VERSION ""

NS_ :

BS_:

BU_: XXX

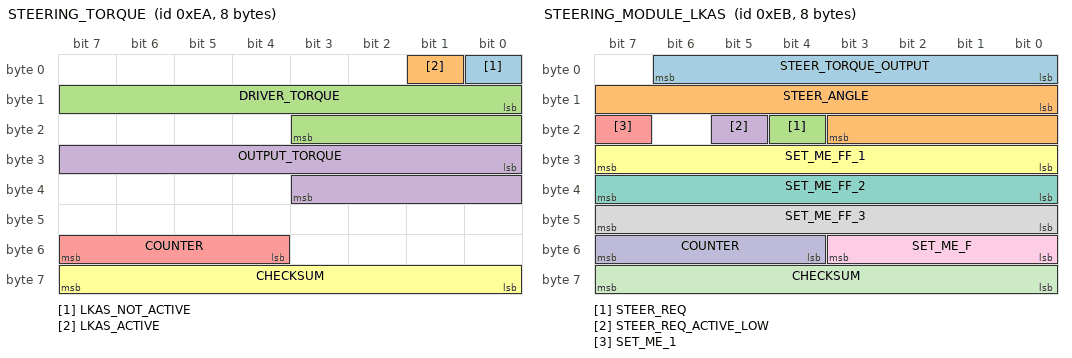
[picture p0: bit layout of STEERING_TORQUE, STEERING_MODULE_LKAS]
BO_ 234 STEERING_TORQUE: 8 XXX
 SG_ LKAS_NOT_ACTIVE : 0|1@0+ (1,0) [0|1] "" XXX
 SG_ LKAS_ACTIVE : 1|1@0+ (1,0) [0|1] "" XXX
 SG_ DRIVER_TORQUE : 8|12@1- (1,0) [0|4095] "" XXX
 SG_ OUTPUT_TORQUE : 24|12@1+ (1,-2000) [0|4095] "" XXX
 SG_ COUNTER : 55|4@0+ (1,0) [0|15] "" XXX
 SG_ CHECKSUM : 63|8@0+ (1,0) [0|255] "" XXX

BO_ 235 STEERING_MODULE_LKAS: 8 XXX
 SG_ STEER_TORQUE_OUTPUT : 0|7@1+ (1,0) [0|255] "" XXX
 SG_ STEER_ANGLE : 8|12@1- (1,0) [0|4095] "" XXX
 SG_ STEER_REQ : 20|1@0+ (1,0) [0|1] "" XXX
 SG_ STEER_REQ_ACTIVE_LOW : 21|1@0+ (1,0) [0|1] "" XXX
 SG_ SET_ME_1 : 23|1@0+ (1,0) [0|1] "" XXX
 SG_ SET_ME_FF_1 : 31|8@0+ (1,0) [0|255] "" XXX
 SG_ SET_ME_FF_2 : 39|8@0+ (1,0) [0|255] "" XXX
 SG_ SET_ME_FF_3 : 47|8@0+ (1,0) [0|255] "" XXX
 SG_ SET_ME_F : 51|4@0+ (1,0) [0|15] "" XXX
 SG_ COUNTER : 55|4@0+ (1,0) [0|15] "" XXX
 SG_ CHECKSUM : 63|8@0+ (1,0) [0|255] "" XXX

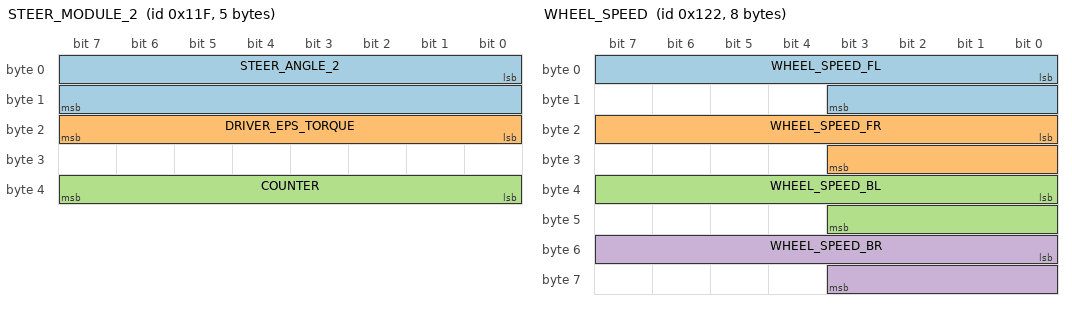
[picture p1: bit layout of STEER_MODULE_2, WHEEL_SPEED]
BO_ 287 STEER_MODULE_2: 5 XXX
 SG_ STEER_ANGLE_2 : 0|16@1- (0.1,0) [0|65535] "deg" XXX
 SG_ DRIVER_EPS_TORQUE : 16|8@1+ (1,0) [0|255] "" XXX
 SG_ COUNTER : 39|8@0+ (1,0) [0|255] "" XXX

BO_ 289 WHEEL_SPEED_1: 8 XXX
 SG_ AVERAGE_WHEEL_SPEED : 0|11@1+ (0.0718,0) [0|2047] "km/h" XXX

BO_ 290 WHEEL_SPEED: 8 XXX
 SG_ WHEEL_SPEED_FL : 0|12@1+ (0.0718,0) [0|65535] "km/h" XXX
 SG_ WHEEL_SPEED_FR : 16|12@1+ (0.0718,0) [0|65535] "km/h" XXX
 SG_ WHEEL_SPEED_BL : 32|12@1+ (0.0718,0) [0|4095] "km/h" XXX
 SG_ WHEEL_SPEED_BR : 48|12@1+ (0.0718,0) [0|65535] "km/h" XXX

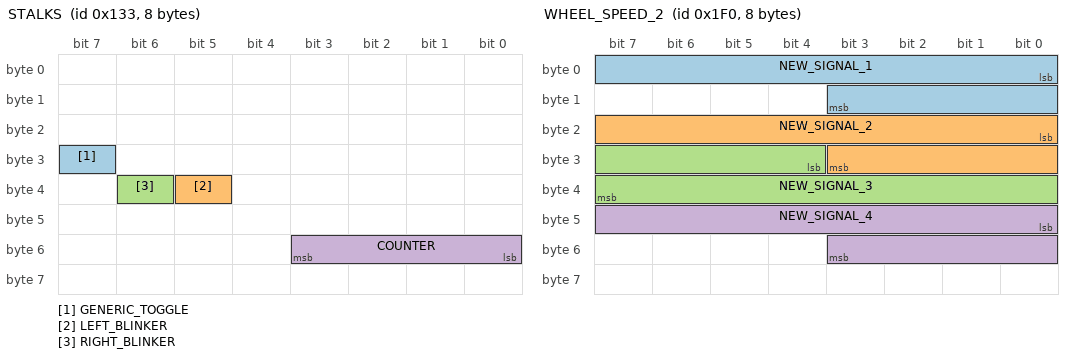
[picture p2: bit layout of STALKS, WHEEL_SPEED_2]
BO_ 307 STALKS: 8 XXX
 SG_ GENERIC_TOGGLE : 31|1@0+ (1,0) [0|1] "" XXX
 SG_ LEFT_BLINKER : 37|1@0+ (1,0) [0|1] "" XXX
 SG_ RIGHT_BLINKER : 38|1@0+ (1,0) [0|1] "" XXX
 SG_ COUNTER : 51|4@0+ (1,0) [0|15] "" XXX

BO_ 496 WHEEL_SPEED_2: 8 XXX
 SG_ NEW_SIGNAL_1 : 0|12@1+ (0.0716,0) [0|4095] "" XXX
 SG_ NEW_SIGNAL_2 : 16|12@1+ (0.0716,0) [0|4095] "" XXX
 SG_ NEW_SIGNAL_3 : 28|12@1+ (0.0716,0) [0|4095] "" XXX
 SG_ NEW_SIGNAL_4 : 40|12@1+ (0.0716,0) [0|4095] "" XXX

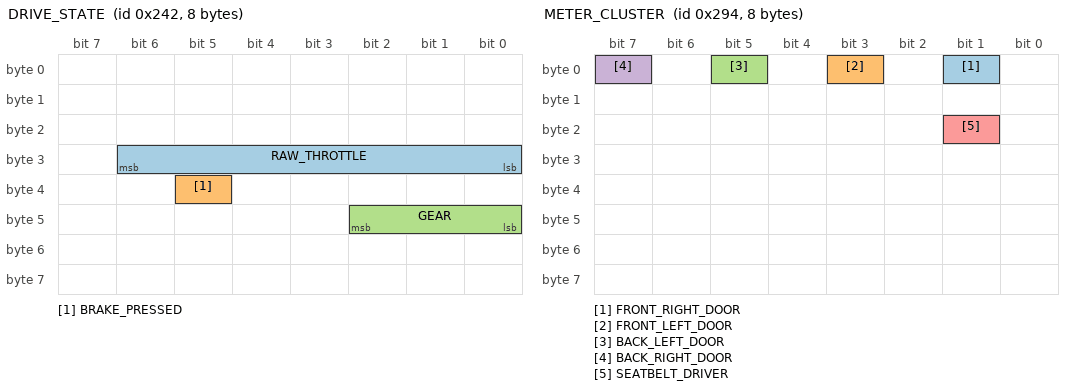
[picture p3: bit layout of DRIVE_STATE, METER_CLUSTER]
BO_ 578 DRIVE_STATE: 8 XXX
 SG_ RAW_THROTTLE : 24|7@1+ (1,0) [0|127] "" XXX
 SG_ BRAKE_PRESSED : 37|1@0+ (1,0) [0|1] "" XXX
 SG_ GEAR : 40|3@1+ (1,0) [0|7] "" XXX

BO_ 660 METER_CLUSTER: 8 XXX
 SG_ FRONT_RIGHT_DOOR : 1|1@0+ (1,0) [0|1] "" XXX
 SG_ FRONT_LEFT_DOOR : 3|1@0+ (1,0) [0|1] "" XXX
 SG_ BACK_LEFT_DOOR : 5|1@0+ (1,0) [0|1] "" XXX
 SG_ BACK_RIGHT_DOOR : 7|1@0+ (1,0) [0|1] "" XXX
 SG_ SEATBELT_DRIVER : 17|1@0+ (1,0) [0|1] "" XXX

BO_ 790 LKAS_HUD_ADAS: 8 XXX
 SG_ HMA : 4|5@0+ (1,0) [0|31] "" XXX
 SG_ STEER_ACTIVE_1_1 : 5|1@0+ (1,0) [0|1] "" XXX
 SG_ LSS_STATE : 7|2@0+ (1,0) [0|3] "" XXX
 SG_ LKAS_X02_1 : 8|2@1+ (1,0) [0|3] "" XXX
 SG_ HAND_WARNING : 10|1@0+ (1,0) [0|1] "" XXX
 SG_ LKAS_X05_1 : 11|5@1+ (1,0) [0|31] "" XXX
 SG_ LKAS_X08_1 : 23|8@0+ (1,0) [0|255] "" XXX
 SG_ LKAS_X08_2 : 31|8@0+ (1,0) [0|255] "" XXX
 SG_ LKAS_X02_2 : 32|2@1+ (1,0) [0|3] "" XXX
 SG_ STEER_ACTIVE_1_3 : 35|1@0+ (1,0) [0|1] "" XXX
 SG_ STEER_ACTIVE_ACTIVE_LOW : 36|1@0+ (1,0) [0|1] "" XXX
 SG_ STEER_ACTIVE_1_2 : 37|1@0+ (1,0) [0|1] "" XXX
 SG_ LKAS_X02_3 : 39|2@0+ (1,0) [0|1] "" XXX
 SG_ LKAS_X08_3 : 47|8@0+ (1,0) [0|255] "" XXX
 SG_ LKAS_X04_1 : 48|4@1+ (1,0) [0|15] "" XXX
 SG_ COUNTER : 55|4@0+ (1,0) [0|15] "" XXX
 SG_ CHECKSUM : 63|8@0+ (1,0) [0|255] "" XXX

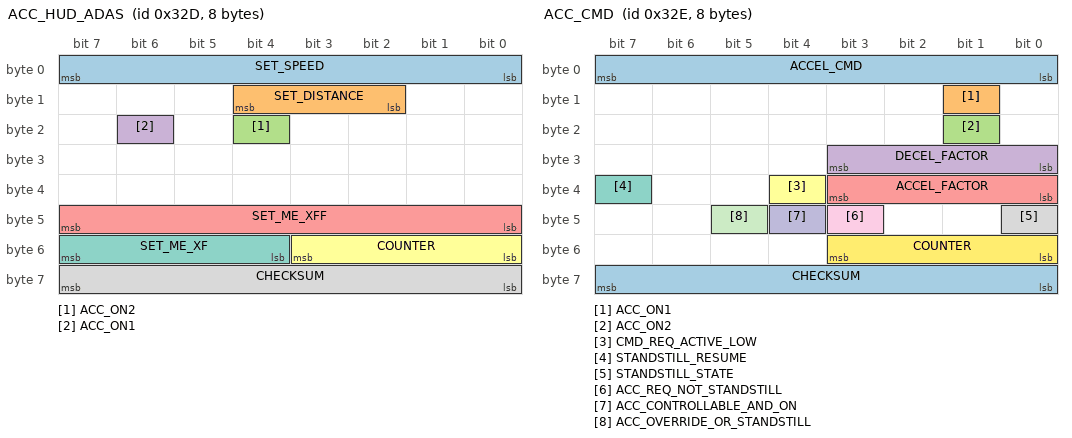
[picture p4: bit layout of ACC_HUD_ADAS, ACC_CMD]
BO_ 813 ACC_HUD_ADAS: 8 XXX
 SG_ SET_SPEED : 0|8@1+ (0.5,0) [0|255] "" XXX
 SG_ SET_DISTANCE : 12|3@0+ (1,0) [0|7] "" XXX
 SG_ ACC_ON2 : 20|1@0+ (1,0) [0|1] "" XXX
 SG_ ACC_ON1 : 22|1@0+ (1,0) [0|1] "" XXX
 SG_ SET_ME_XFF : 47|8@0+ (1,0) [0|255] "" XXX
 SG_ COUNTER : 51|4@0+ (1,0) [0|15] "" XXX
 SG_ SET_ME_XF : 55|4@0+ (1,0) [0|15] "" XXX
 SG_ CHECKSUM : 63|8@0+ (1,0) [0|255] "" XXX

BO_ 814 ACC_CMD: 8 XXX
 SG_ ACCEL_CMD : 0|8@1+ (1,-100) [0|255] "" XXX
 SG_ ACC_ON1 : 9|1@0+ (1,0) [0|1] "" XXX
 SG_ ACC_ON2 : 17|1@0+ (1,0) [0|1] "" XXX
 SG_ DECEL_FACTOR : 24|4@1+ (1,0) [0|15] "" XXX
 SG_ ACCEL_FACTOR : 32|4@1+ (1,0) [0|15] "" XXX
 SG_ CMD_REQ_ACTIVE_LOW : 36|1@0+ (1,0) [0|1] "" XXX
 SG_ STANDSTILL_RESUME : 39|1@0+ (1,0) [0|1] "" XXX
 SG_ STANDSTILL_STATE : 40|1@0+ (1,0) [0|1] "" XXX
 SG_ ACC_REQ_NOT_STANDSTILL : 43|1@0+ (1,0) [0|1] "" XXX
 SG_ ACC_CONTROLLABLE_AND_ON : 44|1@0+ (1,0) [0|1] "" XXX
 SG_ ACC_OVERRIDE_OR_STANDSTILL : 45|1@0+ (1,0) [0|1] "" XXX
 SG_ COUNTER : 48|4@1+ (1,0) [0|15] "" XXX
 SG_ CHECKSUM : 56|8@1+ (1,0) [0|255] "" XXX

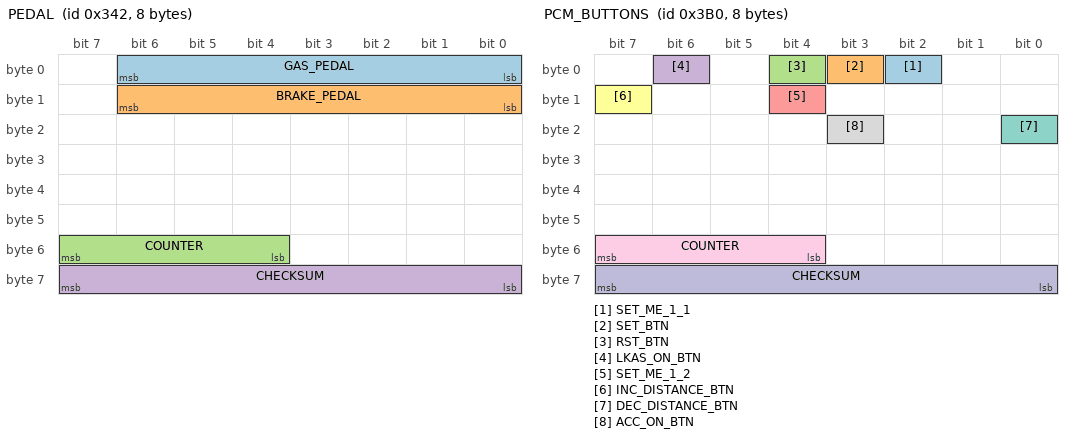
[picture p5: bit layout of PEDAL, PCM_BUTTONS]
BO_ 834 PEDAL: 8 XXX
 SG_ GAS_PEDAL : 0|7@1+ (1,0) [0|127] "%" XXX
 SG_ BRAKE_PEDAL : 8|7@1+ (1,0) [0|127] "%" XXX
 SG_ COUNTER : 52|4@1+ (1,0) [0|15] "" XXX
 SG_ CHECKSUM : 56|8@1+ (1,0) [0|255] "" XXX

BO_ 944 PCM_BUTTONS: 8 0x3B0
 SG_ SET_ME_1_1 : 2|1@0+ (1,0) [0|1] "" XXX
 SG_ SET_BTN : 3|1@0+ (1,0) [0|1] "" XXX
 SG_ RST_BTN : 4|1@0+ (1,0) [0|1] "" XXX
 SG_ LKAS_ON_BTN : 6|1@0+ (1,0) [0|1] "" XXX
 SG_ SET_ME_1_2 : 12|1@0+ (1,0) [0|1] "" XXX
 SG_ INC_DISTANCE_BTN : 15|1@0+ (1,0) [0|1] "" XXX
 SG_ DEC_DISTANCE_BTN : 16|1@0+ (1,0) [0|1] "" XXX
 SG_ ACC_ON_BTN : 19|1@0+ (1,0) [0|1] "" XXX
 SG_ COUNTER : 52|4@1+ (1,0) [0|15] "" XXX
 SG_ CHECKSUM : 63|8@0+ (1,0) [0|255] "" XXX

CM_ SG_ 287 STEER_ANGLE_2 "司机操作的方向盘角度";
CM_ SG_ 287 DRIVER_EPS_TORQUE "司机操作方向盘提供的力矩";
CM_ SG_ 660 FRONT_RIGHT_DOOR "右前门状态";
CM_ SG_ 660 FRONT_LEFT_DOOR "左前门状态";
CM_ SG_ 660 BACK_LEFT_DOOR "左后门状态";
CM_ SG_ 660 BACK_RIGHT_DOOR "右后门状态";
CM_ SG_ 660 SEATBELT_DRIVER "安全带状态";
CM_ SG_ 834 GAS_PEDAL "油门踏板深度";
CM_ SG_ 834 BRAKE_PEDAL "刹车踏板深度";
VAL_ 578 GEAR 4 "D" 2 "R" 1 "P";
VAL_ 790 STEER_ACTIVE_ACTIVE_LOW 0 "功能关闭|激活" 1 "功能开启&未激活";
VAL_ 790 STEER_ACTIVE_1_2 0 "OFF" 1 "ON";
VAL_ 813 SET_DISTANCE 8 "4bar" 4 "3bar" 2 "2bar" 1 "1bar";
